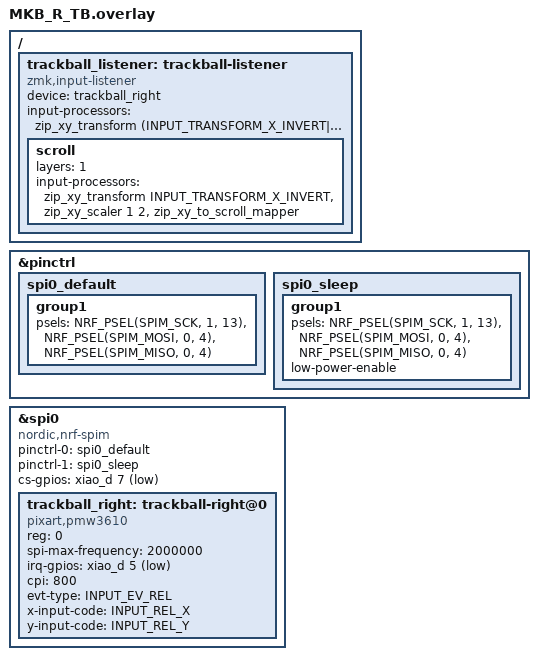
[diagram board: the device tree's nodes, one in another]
&pinctrl {
    spi0_default: spi0_default {
        group1 {
            psels = <NRF_PSEL(SPIM_SCK,  1, 13)>,
                    <NRF_PSEL(SPIM_MOSI, 0, 4)>,
                    <NRF_PSEL(SPIM_MISO, 0, 4)>;
        };
    };

    spi0_sleep: spi0_sleep {
        group1 {
            psels = <NRF_PSEL(SPIM_SCK,  1, 13)>,
                    <NRF_PSEL(SPIM_MOSI, 0, 4)>,
                    <NRF_PSEL(SPIM_MISO, 0, 4)>;
            low-power-enable;
        };
    };
};

&spi0 {
    status = "okay";
    compatible = "nordic,nrf-spim";
    pinctrl-0 = <&spi0_default>;
    pinctrl-1 = <&spi0_sleep>;
    pinctrl-names = "default", "sleep";
    cs-gpios = <&xiao_d 7 GPIO_ACTIVE_LOW>;

    trackball_right: trackball-right@0 {
        status = "okay";
        compatible = "pixart,pmw3610";
        reg = <0>;
        spi-max-frequency = <2000000>;
        irq-gpios = <&xiao_d 5 (GPIO_ACTIVE_LOW | GPIO_PULL_UP)>;
        cpi = <800>;
        evt-type = <INPUT_EV_REL>;
        x-input-code = <INPUT_REL_X>;
        y-input-code = <INPUT_REL_Y>;
    };
};

/ {
    trackball_listener: trackball-listener {
        compatible = "zmk,input-listener";
        status = "okay";
        device = <&trackball_right>;
        input-processors = <&zip_xy_transform (INPUT_TRANSFORM_X_INVERT|INPUT_TRANSFORM_Y_INVERT)>;

        scroll {
            layers = <1>;
            input-processors = <&zip_xy_transform INPUT_TRANSFORM_X_INVERT>, <&zip_xy_scaler 1 2>, <&zip_xy_to_scroll_mapper>;
        };
    }
};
